# ATmega128RFA1 device description
Architecture: AVR8; Family: megaAVR
Registers are 8-bit, access not given, no defined reset value unless marked. A register's access mark holds for its fields unless they carry their own. Offsets are from the block's base; [hi:lo] are bit positions; {n}, {i} and the like mark numbered series; 'fields as' and 'values as' point back to an identical list.

## EEPROM
Instances: EEPROM 0x00
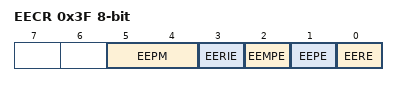
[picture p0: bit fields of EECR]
0x3F EECR — EEPROM Control Register
  [5:4] EEPM — EEPROM Programming Mode
    0=Erase and Write in one operation (Atomic Operation); 1=Erase only; 2=Write only; 3=Reserved for future use
  [3] EERIE — EEPROM Ready Interrupt Enable
  [2] EEMPE — EEPROM Master Write Enable
  [1] EEPE — EEPROM Programming Enable
  [0] EERE — EEPROM Read Enable
0x40 EEDR — EEPROM Data Register
0x41 EEAR 16-bit — EEPROM Address Register Bytes

## JTAG — JTAG Interface
Instances: JTAG 0x00
0x51 OCDR — On-Chip Debug Register
  [7:0] OCDR — On-Chip Debug Register Data
    0=Refer to the debugger documentation for further information on how to use this register
0x54 MCUSR — MCU Status Register
  [4] JTRF — JTAG Reset Flag
0x55 MCUCR — MCU Control Register
  [7] JTD — JTAG Interface Disable

## EXINT — External Interrupts
Instances: EXINT 0x00
0x3B PCIFR — Pin Change Interrupt Flag Register
  [2:0] PCIF — Pin Change Interrupt Flags
0x3C EIFR — External Interrupt Flag Register
  [7:0] INTF — External Interrupt Flag
    0=No edge or logic change on INT7:0 occurred; 1=A edge or logic change on INT0 occurred and triggered an interrupt request; 2=VAL_0x02; 128=A edge or logic change on INT7 occurred and triggered an interrupt request
0x3D EIMSK — External Interrupt Mask Register
  [7:0] INT — External Interrupt Request Enable
    0=All external pin interrupts are disabled; 255=All external pin interrupts are enabled
0x68 PCICR — Pin Change Interrupt Control Register
  [2:0] PCIE — Pin Change Interrupt Enables
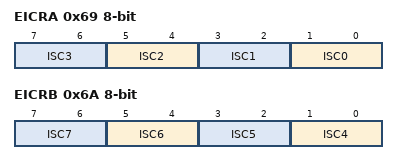
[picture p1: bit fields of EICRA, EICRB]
0x69 EICRA — External Interrupt Control Register A
  [all] fields
    0=The low level of INTn generates an interrupt request; 1=Any edge of INTn generates asynchronously an interrupt request; 2=The falling edge of INTn generates asynchronously an interrupt request; 3=The rising edge of INTn generates asynchronously an interrupt request
  [2n+1:2n] ISC{n} (n=0..3) — External Interrupt {n} Sense Control Bit
0x6A EICRB — External Interrupt Control Register B
  [all] fields
    values as the fields of EICRA
  [2n-7:2n-8] ISC{n} (n=4..7) — External Interrupt {n} Sense Control Bit
0x6B PCMSK0 — Pin Change Mask Register 0
0x6C PCMSK1 — Pin Change Mask Register 1
  [7:0] PCINT (bit 8 of the value upward) — Pin Change Enable Mask
0x6D PCMSK2 — Pin Change Mask Register 2
  [7:0] PCINT (bit 16 of the value upward) — Pin Change Enable Mask

## ADC — Analog-to-Digital Converter
Instances: ADC 0x00
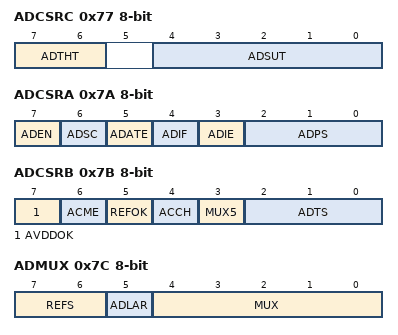
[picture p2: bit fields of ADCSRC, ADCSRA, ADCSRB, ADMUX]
0x77 ADCSRC — The ADC Control and Status Register C
  [7:6] ADTHT — ADC Track-and-Hold Time
    0=Single ended: 1, differential 3 ADC clock cycles; 1=Single ended: 2, differential 5 ADC clock cycles; 2=Single ended: 3, differential 7 ADC clock cycles; 3=Single ended: 4, differential 9 ADC clock cycles
  [4:0] ADSUT — ADC Start-up Time
    0=3 ADC clock cycles; 1=7 ADC clock cycles; 2=11 ADC clock cycles; 3=15 ADC clock cycles; 4=VAL_0x04; 62=251 ADC clock cycles; 63=255 ADC clock cycles
0x78 ADC 16-bit — ADC Data Register Bytes
0x7A ADCSRA — The ADC Control and Status Register A
  [7] ADEN — ADC Enable
  [6] ADSC — ADC Start Conversion
  [5] ADATE — ADC Auto Trigger Enable
  [4] ADIF — ADC Interrupt Flag
  [3] ADIE — ADC Interrupt Enable
  [2:0] ADPS — ADC Prescaler Select Bits
    0=2; 1=2; 2=4; 3=8; 4=16; 5=32; 6=64; 7=128
0x7B ADCSRB — The ADC Control and Status Register B
  [7] AVDDOK — AVDD Supply Voltage OK
  [6] ACME — Analog Comparator Multiplexer Enable
  [5] REFOK — Reference Voltage OK
  [4] ACCH — Analog Channel Change
  [3] MUX5 — Analog Channel and Gain Selection Bits
  [2:0] ADTS — ADC Auto Trigger Source
    0=Free Running mode; 1=Analog Comparator; 2=External Interrupt Request 0; 3=Timer/Counter0 Compare Match A; 4=Timer/Counter0 Overflow; 5=Timer/Counter1 Compare Match B; 6=Timer/Counter1 Overflow; 7=Timer/Counter1 Capture Event
0x7C ADMUX — The ADC Multiplexer Selection Register
  [7:6] REFS — Reference Selection Bits
    0=AREF, Internal reference voltage generation turned off; 1=AVDD with external capacitor at AREF pin; 2=Internal 1.5V Voltage Reference (no external capacitor at AREF pin); 3=Internal 1.6V Voltage Reference (no external capacitor at AREF pin)
  [5] ADLAR — ADC Left Adjust Result
  [4:0] MUX — Analog Channel and Gain Selection Bits
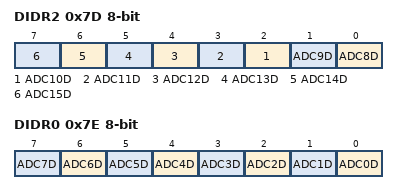
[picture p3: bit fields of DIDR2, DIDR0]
0x7D DIDR2 — Digital Input Disable Register 2
  [n-8] ADC{n}D (n=8..15) — Reserved Bits
0x7E DIDR0 — Digital Input Disable Register 0
  [n] ADC{n}D (n=0..7) — Disable ADC7:0 Digital Input
